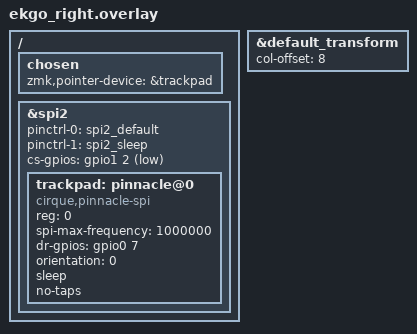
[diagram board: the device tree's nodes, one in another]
#include "ekgo.dtsi"


&default_transform {
    col-offset = <8>;
};


/ {
       chosen {
        zmk,pointer-device = &trackpad;
    };

    &spi2 {
        status = "okay";
        pinctrl-0 = <&spi2_default>;
        pinctrl-1 = <&spi2_sleep>;
        pinctrl-names = "default", "sleep";
        cs-gpios = <&gpio1 2 GPIO_ACTIVE_LOW>;

        trackpad: pinnacle@0 {
            compatible = "cirque,pinnacle-spi";
            reg = <0>;
            spi-max-frequency = <1000000>;
            dr-gpios = <&gpio0 7 GPIO_ACTIVE_HIGH>;
            orientation = <0>; // Adjust (0, 90, 180, 270) based on mounting
            sleep;
            no-taps; // Optional; adjust as needed
            status = "okay";
        };
    };
};
